# PSS_356.0 register map
Vendor: Texas Instruments
Peripheral module from a debugger description file (folder MSP432).
Registers are 32-bit, read-write, no defined reset value unless marked. A register's access mark holds for its fields unless they carry their own. Offsets are as the file gives them; lines under a group give offsets from that group; [hi:lo] are bit positions; {n}, {i} and the like mark numbered series; 'fields as' and 'values as' point back to an identical list; <NAME> marks a mode.

## PSS
0x00 PSSKEY — Key Register
  [15:0] PSSKEY — PSS control key
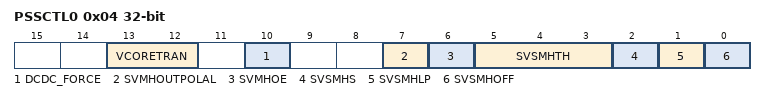
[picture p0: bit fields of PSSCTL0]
0x04 PSSCTL0 — Control 0 Register
  [13:12] VCORETRAN — Controls core voltage level transition time
    0=32 s / 100 mV; 1=64 s / 100 mV; 2=128 s / 100 mV (default); 3=256 s / 100 mV
  [10] DCDC_FORCE — Force DC-DC regulator operation
    0=DC-DC regulator operation not forced. Automatic fail-safe mechanism switches the core voltage regulator from DC-DC to LDO when the supply voltage falls below the minimum supply voltage necessary for DC-DC operation.; 1=DC-DC regulator operation forced. Automatic fail-safe mechanism is disabled and device continues to operate out of DC-DC regulator.
  [7] SVMHOUTPOLAL — SVMHOUT pin polarity active low
    0=SVMHOUT is active high. An error condition is signaled by a 1 at the SVMHOUT pin; 1=SVMHOUT is active low. An error condition is signaled by a 0 at the SVMHOUT pin
  [6] SVMHOE — SVSM high-side output enable
    0=SVSMHIFG bit is not output; 1=SVSMHIFG bit is output to the device SVMHOUT pin. The device-specific port logic must be configured accordingly
  [5:3] SVSMHTH — SVSM high-side reset voltage level
  [2] SVSMHS — Supply supervisor or monitor selection for the high-side
    0=Configure as SVSH; 1=Configure as SVMH
  [1] SVSMHLP — SVSM high-side low power normal performance mode
    0=Full performance mode. See the device-specific data sheet for response times.; 1=Low power normal performance mode in LPM3, LPM4, and LPMx.5, full performance in all other modes. See the device-specific data sheet for response times.
  [0] SVSMHOFF — SVSM high-side off
    0=The SVSMH is on; 1=The SVSMH is off
0x34 PSSIE — Interrupt Enable Register
  [1] SVSMHIE — High-side SVSM interrupt enable
    0=Interrupt disabled; 1=Interrupt enabled
0x38 PSSIFG ro — Interrupt Flag Register
  [1] SVSMHIFG — High-side SVSM interrupt flag
    0=No interrupt pending; 1=Interrupt due to SVSMH
0x3C PSSCLRIFG — Clear Interrupt Flag Register
  [1] CLRSVSMHIFG — SVSMH clear interrupt flag
    0=No effect; 1=Clear pending interrupt flag
